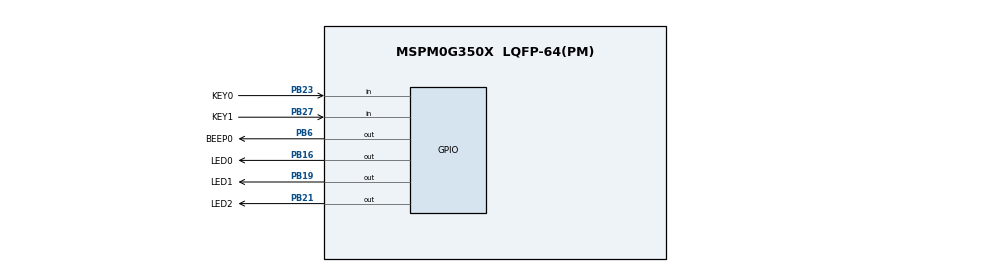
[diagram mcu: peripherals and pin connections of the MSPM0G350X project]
/**
 * @cliArgs --device "MSPM0G350X" --part "Default" --package "LQFP-64(PM)" --product "mspm0_sdk@2.05.00.05"
 * @versions {"tool":"1.26.3+4558"}
 */

/**
 * Import the modules used in this configuration.
 */
const Board  = scripting.addModule("/ti/driverlib/Board");
const GPIO   = scripting.addModule("/ti/driverlib/GPIO", {}, false);
const GPIO1  = GPIO.addInstance();
const GPIO2  = GPIO.addInstance();
const GPIO3  = GPIO.addInstance();
const SYSCTL = scripting.addModule("/ti/driverlib/SYSCTL");

/**
 * Write custom configuration values to the imported modules.
 */
const divider9       = system.clockTree["UDIV"];
divider9.divideValue = 2;

const multiplier2         = system.clockTree["PLL_QDIV"];
multiplier2.multiplyValue = 4;

const mux4       = system.clockTree["EXHFMUX"];
mux4.inputSelect = "EXHFMUX_XTAL";

const mux8       = system.clockTree["HSCLKMUX"];
mux8.inputSelect = "HSCLKMUX_SYSPLL0";

const mux12       = system.clockTree["SYSPLLMUX"];
mux12.inputSelect = "zSYSPLLMUX_HFCLK";

const pinFunction4     = system.clockTree["HFXT"];
pinFunction4.enable    = true;
pinFunction4.inputFreq = 40;


GPIO1.$name                          = "LED";
GPIO1.portSegment                    = "Upper";
GPIO1.associatedPins.create(3);
GPIO1.associatedPins[0].$name        = "LED0";
GPIO1.associatedPins[0].ioStructure  = "SD";
GPIO1.associatedPins[0].assignedPort = "PORTB";
GPIO1.associatedPins[0].pin.$assign  = "PB16";
GPIO1.associatedPins[1].$name        = "LED1";
GPIO1.associatedPins[1].assignedPort = "PORTB";
GPIO1.associatedPins[1].initialValue = "SET";
GPIO1.associatedPins[1].pin.$assign  = "PB19";
GPIO1.associatedPins[2].$name        = "LED2";
GPIO1.associatedPins[2].initialValue = "SET";
GPIO1.associatedPins[2].assignedPort = "PORTB";
GPIO1.associatedPins[2].pin.$assign  = "PB21";

GPIO2.$name                              = "KEY";
GPIO2.associatedPins.create(2);
GPIO2.associatedPins[0].$name            = "KEY0";
GPIO2.associatedPins[0].direction        = "INPUT";
GPIO2.associatedPins[0].ioStructure      = "SD";
GPIO2.associatedPins[0].assignedPort     = "PORTB";
GPIO2.associatedPins[0].internalResistor = "PULL_DOWN";
GPIO2.associatedPins[0].pin.$assign      = "PB23";
GPIO2.associatedPins[1].$name            = "KEY1";
GPIO2.associatedPins[1].direction        = "INPUT";
GPIO2.associatedPins[1].ioStructure      = "SD";
GPIO2.associatedPins[1].assignedPort     = "PORTB";
GPIO2.associatedPins[1].internalResistor = "PULL_DOWN";
GPIO2.associatedPins[1].pin.$assign      = "PB27";

GPIO3.$name                         = "BEEP";
GPIO3.port                          = "PORTB";
GPIO3.associatedPins[0].$name       = "BEEP0";
GPIO3.associatedPins[0].pin.$assign = "PB6";

SYSCTL.clockTreeEn = true;

/**
 * Pinmux solution for unlocked pins/peripherals. This ensures that minor changes to the automatic solver in a future
 * version of the tool will not impact the pinmux you originally saw.  These lines can be completely deleted in order to
 * re-solve from scratch.
 */
pinFunction4.peripheral.$suggestSolution           = "SYSCTL";
pinFunction4.peripheral.hfxInPin.$suggestSolution  = "PA5";
pinFunction4.peripheral.hfxOutPin.$suggestSolution = "PA6";
Board.peripheral.$suggestSolution                  = "DEBUGSS";
Board.peripheral.swclkPin.$suggestSolution         = "PA20";
Board.peripheral.swdioPin.$suggestSolution         = "PA19";
